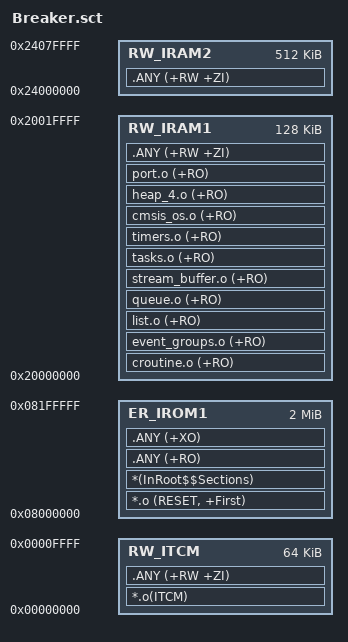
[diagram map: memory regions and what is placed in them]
; *************************************************************
; *** Scatter-Loading Description File generated by uVision ***
; *************************************************************

LR_IROM1 0x08000000 0x00200000  {    ; load region size_region
  ER_IROM1 0x08000000 0x00200000  {  ; load address = execution address
   *.o (RESET, +First)
   *(InRoot$$Sections)
   .ANY (+RO)
   .ANY (+XO)
  }
  RW_ITCM 0x00000000 0x00010000 {
   *.o(ITCM)
	.ANY (+RW +ZI)
  }
  RW_IRAM1 0x20000000 0x00020000  {  ; RW data
    croutine.o (+RO)
    event_groups.o (+RO)
    list.o (+RO)
    queue.o (+RO)
    stream_buffer.o (+RO)
    tasks.o (+RO)
    timers.o (+RO)
    cmsis_os.o (+RO)
    heap_4.o (+RO)
    port.o (+RO)
   .ANY (+RW +ZI)
  }
  RW_IRAM2 0x24000000 0x00080000  {
   .ANY (+RW +ZI)
  }
}

